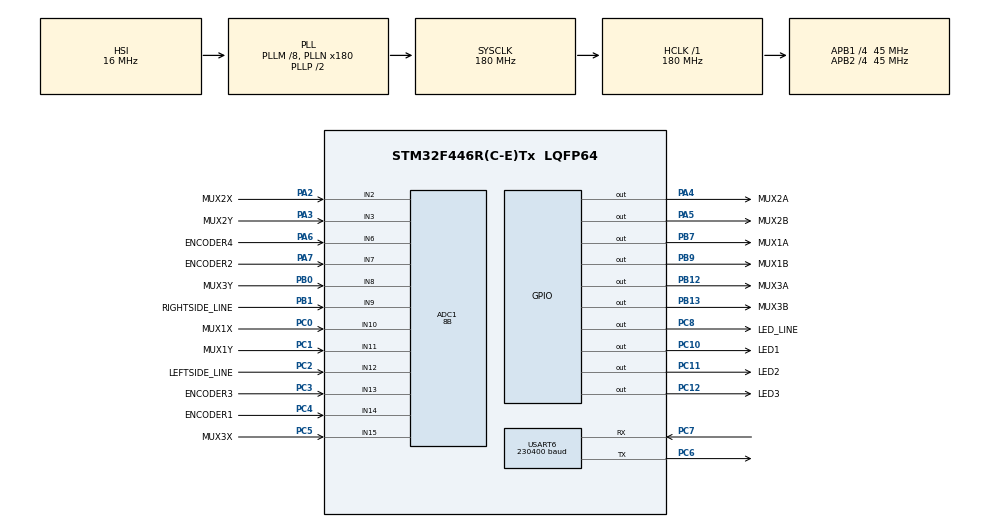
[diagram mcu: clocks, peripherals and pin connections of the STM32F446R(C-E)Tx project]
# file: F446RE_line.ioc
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ADC1.Channel-0\#ChannelRegularConversion=ADC_CHANNEL_14
ADC1.Channel-1\#ChannelRegularConversion=ADC_CHANNEL_7
ADC1.Channel-10\#ChannelRegularConversion=ADC_CHANNEL_15
ADC1.Channel-11\#ChannelRegularConversion=ADC_CHANNEL_8
ADC1.Channel-2\#ChannelRegularConversion=ADC_CHANNEL_13
ADC1.Channel-3\#ChannelRegularConversion=ADC_CHANNEL_6
ADC1.Channel-4\#ChannelRegularConversion=ADC_CHANNEL_12
ADC1.Channel-5\#ChannelRegularConversion=ADC_CHANNEL_9
ADC1.Channel-6\#ChannelRegularConversion=ADC_CHANNEL_10
ADC1.Channel-7\#ChannelRegularConversion=ADC_CHANNEL_11
ADC1.Channel-8\#ChannelRegularConversion=ADC_CHANNEL_2
ADC1.Channel-9\#ChannelRegularConversion=ADC_CHANNEL_3
ADC1.ContinuousConvMode=ENABLE
ADC1.DMAContinuousRequests=ENABLE
ADC1.NbrOfConversion=12
ADC1.NbrOfConversionFlag=1
ADC1.Rank-0\#ChannelRegularConversion=1
ADC1.Rank-1\#ChannelRegularConversion=2
ADC1.Rank-10\#ChannelRegularConversion=11
ADC1.Rank-11\#ChannelRegularConversion=12
ADC1.Rank-2\#ChannelRegularConversion=3
ADC1.Rank-3\#ChannelRegularConversion=4
ADC1.Rank-4\#ChannelRegularConversion=5
ADC1.Rank-5\#ChannelRegularConversion=6
ADC1.Rank-6\#ChannelRegularConversion=7
ADC1.Rank-7\#ChannelRegularConversion=8
ADC1.Rank-8\#ChannelRegularConversion=9
ADC1.Rank-9\#ChannelRegularConversion=10
ADC1.Resolution=ADC_RESOLUTION_8B
ADC1.SamplingTime-0\#ChannelRegularConversion=ADC_SAMPLETIME_15CYCLES
ADC1.SamplingTime-1\#ChannelRegularConversion=ADC_SAMPLETIME_15CYCLES
ADC1.SamplingTime-10\#ChannelRegularConversion=ADC_SAMPLETIME_56CYCLES
ADC1.SamplingTime-11\#ChannelRegularConversion=ADC_SAMPLETIME_56CYCLES
ADC1.SamplingTime-2\#ChannelRegularConversion=ADC_SAMPLETIME_15CYCLES
ADC1.SamplingTime-3\#ChannelRegularConversion=ADC_SAMPLETIME_15CYCLES
ADC1.SamplingTime-4\#ChannelRegularConversion=ADC_SAMPLETIME_56CYCLES
ADC1.SamplingTime-5\#ChannelRegularConversion=ADC_SAMPLETIME_56CYCLES
ADC1.SamplingTime-6\#ChannelRegularConversion=ADC_SAMPLETIME_56CYCLES
ADC1.SamplingTime-7\#ChannelRegularConversion=ADC_SAMPLETIME_56CYCLES
ADC1.SamplingTime-8\#ChannelRegularConversion=ADC_SAMPLETIME_56CYCLES
ADC1.SamplingTime-9\#ChannelRegularConversion=ADC_SAMPLETIME_56CYCLES
ADC1.ScanConvMode=ENABLE
ADC1.master=1
Dma.ADC1.2.Direction=DMA_PERIPH_TO_MEMORY
Dma.ADC1.2.FIFOMode=DMA_FIFOMODE_DISABLE
Dma.ADC1.2.Instance=DMA2_Stream0
Dma.ADC1.2.MemDataAlignment=DMA_MDATAALIGN_HALFWORD
Dma.ADC1.2.MemInc=DMA_MINC_ENABLE
Dma.ADC1.2.Mode=DMA_CIRCULAR
Dma.ADC1.2.PeriphDataAlignment=DMA_PDATAALIGN_HALFWORD
Dma.ADC1.2.PeriphInc=DMA_PINC_DISABLE
Dma.ADC1.2.Priority=DMA_PRIORITY_LOW
Dma.Request0=USART6_RX
Dma.Request1=USART6_TX
Dma.Request2=ADC1
Dma.USART6_RX.0.Direction=DMA_PERIPH_TO_MEMORY
Dma.USART6_RX.0.FIFOMode=DMA_FIFOMODE_DISABLE
Dma.USART6_RX.0.Instance=DMA2_Stream1
Dma.USART6_RX.0.MemDataAlignment=DMA_MDATAALIGN_BYTE
Dma.USART6_RX.0.MemInc=DMA_MINC_ENABLE
Dma.USART6_RX.0.Mode=DMA_CIRCULAR
Dma.USART6_RX.0.PeriphDataAlignment=DMA_PDATAALIGN_BYTE
Dma.USART6_RX.0.PeriphInc=DMA_PINC_DISABLE
Dma.USART6_RX.0.Priority=DMA_PRIORITY_LOW
Dma.USART6_TX.1.Direction=DMA_MEMORY_TO_PERIPH
Dma.USART6_TX.1.FIFOMode=DMA_FIFOMODE_DISABLE
Dma.USART6_TX.1.Instance=DMA2_Stream6
Dma.USART6_TX.1.MemDataAlignment=DMA_MDATAALIGN_BYTE
Dma.USART6_TX.1.MemInc=DMA_MINC_ENABLE
Dma.USART6_TX.1.Mode=DMA_CIRCULAR
Dma.USART6_TX.1.PeriphDataAlignment=DMA_PDATAALIGN_BYTE
Dma.USART6_TX.1.PeriphInc=DMA_PINC_DISABLE
Dma.USART6_TX.1.Priority=DMA_PRIORITY_LOW
Mcu.Family=STM32F4
Mcu.Name=STM32F446R(C-E)Tx
Mcu.Package=LQFP64
NVIC.DMA2_Stream0_IRQn=true\:0\:0\:false\:false\:true\:false\:true\:true
NVIC.DMA2_Stream1_IRQn=true\:0\:0\:false\:false\:true\:false\:true\:true
NVIC.DMA2_Stream6_IRQn=true\:0\:0\:false\:false\:true\:false\:true\:true
NVIC.PriorityGroup=NVIC_PRIORITYGROUP_4
NVIC.TIM1_UP_TIM10_IRQn=true\:0\:0\:false\:false\:true\:true\:true\:true
NVIC.USART6_IRQn=true\:0\:0\:false\:false\:true\:false\:true\:true
PA2.GPIO_Label=MUX2X
PA2.Signal=ADCx_IN2
PA3.GPIO_Label=MUX2Y
PA3.Signal=ADCx_IN3
PA4.GPIO_Label=MUX2A
PA4.Signal=GPIO_Output
PA5.GPIO_Label=MUX2B
PA5.Signal=GPIO_Output
PA6.GPIO_Label=ENCODER4
PA6.Signal=ADCx_IN6
PA7.GPIO_Label=ENCODER2
PA7.Signal=ADCx_IN7
PB0.GPIO_Label=MUX3Y
PB0.Signal=ADCx_IN8
PB1.GPIO_Label=RIGHTSIDE_LINE
PB1.Signal=ADCx_IN9
PB12.GPIO_Label=MUX3A
PB12.Signal=GPIO_Output
PB13.GPIO_Label=MUX3B
PB13.Signal=GPIO_Output
PB7.GPIO_Label=MUX1A
PB7.Signal=GPIO_Output
PB9.GPIO_Label=MUX1B
PB9.Signal=GPIO_Output
PC0.GPIO_Label=MUX1X
PC0.Signal=ADCx_IN10
PC1.GPIO_Label=MUX1Y
PC1.Signal=ADCx_IN11
PC10.GPIO_Label=LED1
PC10.Signal=GPIO_Output
PC11.GPIO_Label=LED2
PC11.Signal=GPIO_Output
PC12.GPIO_Label=LED3
PC12.Signal=GPIO_Output
PC2.GPIO_Label=LEFTSIDE_LINE
PC2.Signal=ADCx_IN12
PC3.GPIO_Label=ENCODER3
PC3.Signal=ADCx_IN13
PC4.GPIO_Label=ENCODER1
PC4.Signal=ADCx_IN14
PC5.GPIO_Label=MUX3X
PC5.Signal=ADCx_IN15
PC6.Mode=Asynchronous
PC6.Signal=USART6_TX
PC7.Mode=Asynchronous
PC7.Signal=USART6_RX
PC8.GPIO_Label=LED_LINE
PC8.Signal=GPIO_Output
ProjectManager.HeapSize=0x200
ProjectManager.StackSize=0x400
ProjectManager.TargetToolchain=Makefile
RCC.AHBFreq_Value=180000000
RCC.APB1CLKDivider=RCC_HCLK_DIV4
RCC.APB1Freq_Value=45000000
RCC.APB1TimFreq_Value=90000000
RCC.APB2CLKDivider=RCC_HCLK_DIV4
RCC.APB2Freq_Value=45000000
RCC.APB2TimFreq_Value=90000000
RCC.CortexFreq_Value=180000000
RCC.HCLKFreq_Value=180000000
RCC.PLLM=8
RCC.PLLN=180
RCC.SYSCLKFreq_VALUE=180000000
RCC.SYSCLKSource=RCC_SYSCLKSOURCE_PLLCLK
RCC.USBFreq_Value=180000000
RCC.VCOOutputFreq_Value=360000000
SH.ADCx_IN10.0=ADC1_IN10,IN10
SH.ADCx_IN11.0=ADC1_IN11,IN11
SH.ADCx_IN12.0=ADC1_IN12,IN12
SH.ADCx_IN13.0=ADC1_IN13,IN13
SH.ADCx_IN14.0=ADC1_IN14,IN14
SH.ADCx_IN15.0=ADC1_IN15,IN15
SH.ADCx_IN2.0=ADC1_IN2,IN2
SH.ADCx_IN3.0=ADC1_IN3,IN3
SH.ADCx_IN6.0=ADC1_IN6,IN6
SH.ADCx_IN7.0=ADC1_IN7,IN7
SH.ADCx_IN8.0=ADC1_IN8,IN8
SH.ADCx_IN9.0=ADC1_IN9,IN9
TIM10.Period=1
TIM10.Prescaler=8999
USART6.BaudRate=230400
USART6.VirtualMode=VM_ASYNC
VP_TIM10_VS_ClockSourceINT.Mode=Enable_Timer
board=custom

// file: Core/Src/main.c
/* USER CODE BEGIN Header */
/**
 ******************************************************************************
 * @file           : main.c
 * @brief          : Main program body
 ******************************************************************************
 * @attention
 *
 * Copyright (c) 2025 STMicroelectronics.
 * All rights reserved.
 *
 * This software is licensed under terms that can be found in the LICENSE file
 * in the root directory of this software component.
 * If no LICENSE file comes with this software, it is provided AS-IS.
 *
 ******************************************************************************
 */
/* USER CODE END Header */
#include "main.h"

#include "adc.h"
#include "dma.h"
#include "gpio.h"
#include "tim.h"
#include "usart.h"

void SystemClock_Config(void);

/* USER CODE BEGIN 0 */
void HAL_TIM_PeriodElapsedCallback(TIM_HandleTypeDef *htim) {
      if (htim == &htim10) {
            TimInterrupt5khz();
      }
}
/* USER CODE END 0 */

int main(void) {

      /* MCU Configuration--------------------------------------------------------*/

      /* Reset of all peripherals, Initializes the Flash interface and the Systick. */
      HAL_Init();

      /* Configure the system clock */
      SystemClock_Config();

      /* Initialize all configured peripherals */
      MX_GPIO_Init();
      MX_DMA_Init();
      MX_ADC1_Init();
      MX_USART6_UART_Init();
      MX_TIM10_Init();
      /* USER CODE BEGIN 2 */
      setup();
      HAL_TIM_Base_Start_IT(&htim10);
      /* USER CODE END 2 */

      /* Infinite loop */
      /* USER CODE BEGIN WHILE */
      main_app();
      while (1) {
            /* USER CODE END WHILE */

      }
}

void SystemClock_Config(void) {
      RCC_OscInitTypeDef RCC_OscInitStruct = {0};
      RCC_ClkInitTypeDef RCC_ClkInitStruct = {0};

      /** Configure the main internal regulator output voltage
       */
      __HAL_RCC_PWR_CLK_ENABLE();
      __HAL_PWR_VOLTAGESCALING_CONFIG(PWR_REGULATOR_VOLTAGE_SCALE1);

      /** Initializes the RCC Oscillators according to the specified parameters
       * in the RCC_OscInitTypeDef structure.
       */
      RCC_OscInitStruct.OscillatorType = RCC_OSCILLATORTYPE_HSI;
      RCC_OscInitStruct.HSIState = RCC_HSI_ON;
      RCC_OscInitStruct.HSICalibrationValue = RCC_HSICALIBRATION_DEFAULT;
      RCC_OscInitStruct.PLL.PLLState = RCC_PLL_ON;
      RCC_OscInitStruct.PLL.PLLSource = RCC_PLLSOURCE_HSI;
      RCC_OscInitStruct.PLL.PLLM = 8;
      RCC_OscInitStruct.PLL.PLLN = 180;
      RCC_OscInitStruct.PLL.PLLP = RCC_PLLP_DIV2;
      RCC_OscInitStruct.PLL.PLLQ = 2;
      RCC_OscInitStruct.PLL.PLLR = 2;
      if (HAL_RCC_OscConfig(&RCC_OscInitStruct) != HAL_OK) {
            Error_Handler();
      }

      /** Activate the Over-Drive mode
       */
      if (HAL_PWREx_EnableOverDrive() != HAL_OK) {
            Error_Handler();
      }

      /** Initializes the CPU, AHB and APB buses clocks
       */
      RCC_ClkInitStruct.ClockType = RCC_CLOCKTYPE_HCLK | RCC_CLOCKTYPE_SYSCLK | RCC_CLOCKTYPE_PCLK1 | RCC_CLOCKTYPE_PCLK2;
      RCC_ClkInitStruct.SYSCLKSource = RCC_SYSCLKSOURCE_PLLCLK;
      RCC_ClkInitStruct.AHBCLKDivider = RCC_SYSCLK_DIV1;
      RCC_ClkInitStruct.APB1CLKDivider = RCC_HCLK_DIV4;
      RCC_ClkInitStruct.APB2CLKDivider = RCC_HCLK_DIV4;

      if (HAL_RCC_ClockConfig(&RCC_ClkInitStruct, FLASH_LATENCY_5) != HAL_OK) {
            Error_Handler();
      }
}

void Error_Handler(void) {
      __disable_irq();
      while (1) {
      }
}
